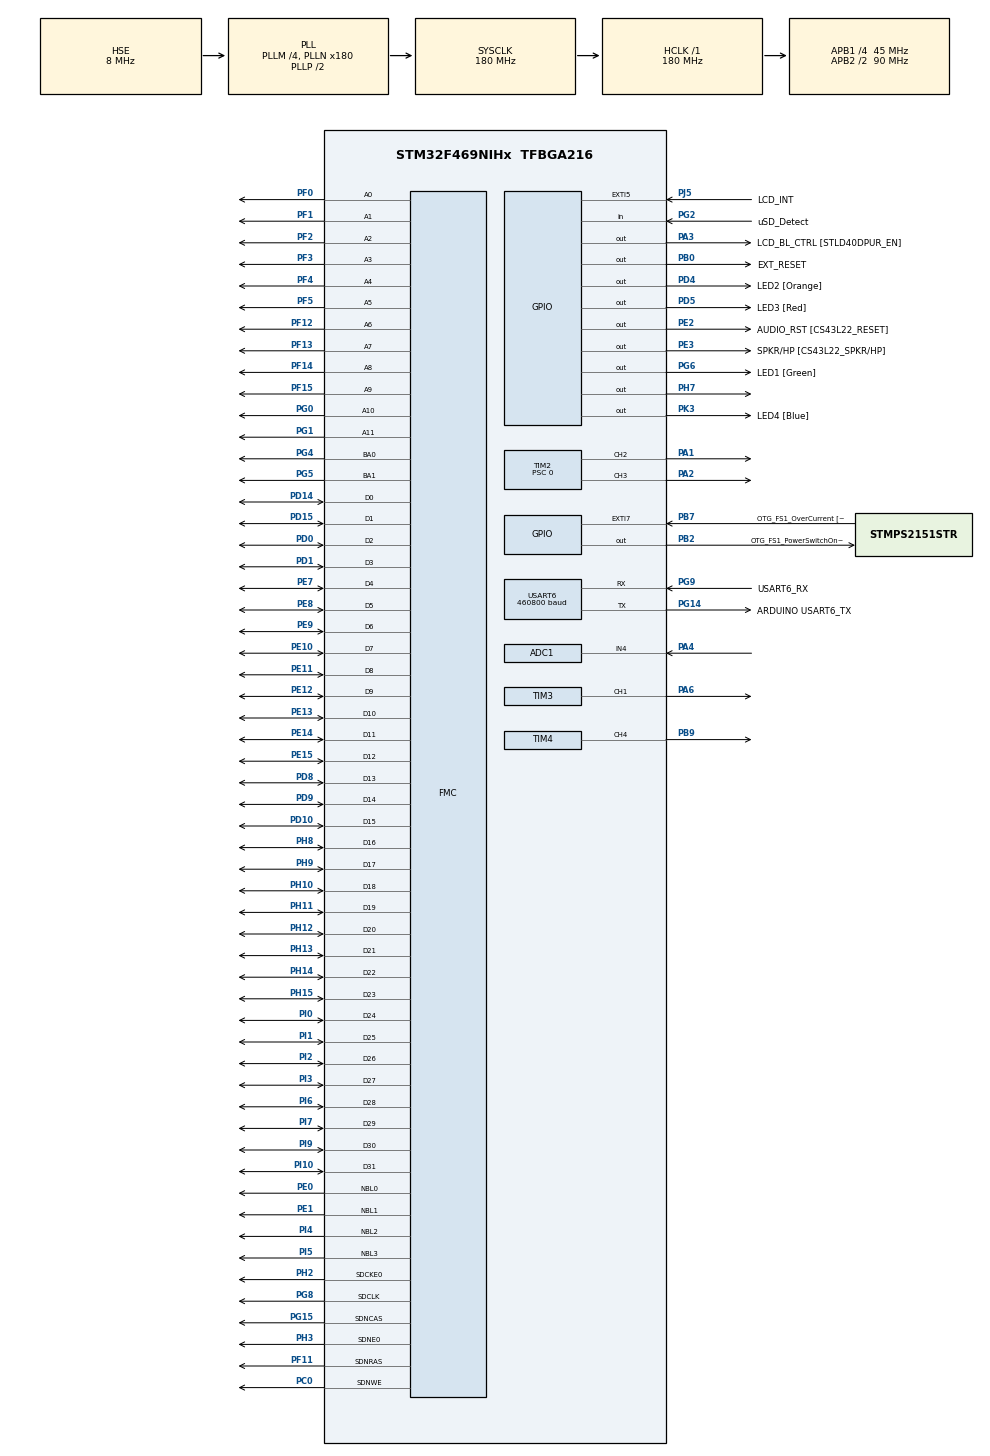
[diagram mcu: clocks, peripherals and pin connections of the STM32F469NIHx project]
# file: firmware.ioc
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ADC1.Channel-0\#ChannelRegularConversion=ADC_CHANNEL_4
ADC1.ExternalTrigConv=ADC_EXTERNALTRIGCONV_T4_CC4
ADC1.NbrOfConversion=1
ADC1.NbrOfConversionFlag=1
ADC1.Rank-0\#ChannelRegularConversion=1
ADC1.SamplingTime-0\#ChannelRegularConversion=ADC_SAMPLETIME_28CYCLES
ADC1.master=1
DSIHOST_CKN.GPIO_Label=DSI_CK_N
DSIHOST_CKN.Signal=DSIHOST_CKN
DSIHOST_CKP.GPIO_Label=DSI_CK_P
DSIHOST_CKP.Signal=DSIHOST_CKP
DSIHOST_D0N.GPIO_Label=DSI_D0_N
DSIHOST_D0N.Signal=DSIHOST_D0N
DSIHOST_D0P.GPIO_Label=DSI_D0_P
DSIHOST_D0P.Signal=DSIHOST_D0P
DSIHOST_D1N.GPIO_Label=DSI_D1_N
DSIHOST_D1N.Signal=DSIHOST_D1N
DSIHOST_D1P.GPIO_Label=DSI_D1_P
DSIHOST_D1P.Signal=DSIHOST_D1P
Dma.ADC1.2.Direction=DMA_PERIPH_TO_MEMORY
Dma.ADC1.2.FIFOMode=DMA_FIFOMODE_DISABLE
Dma.ADC1.2.Instance=DMA2_Stream0
Dma.ADC1.2.MemDataAlignment=DMA_MDATAALIGN_HALFWORD
Dma.ADC1.2.MemInc=DMA_MINC_ENABLE
Dma.ADC1.2.Mode=DMA_NORMAL
Dma.ADC1.2.PeriphDataAlignment=DMA_PDATAALIGN_HALFWORD
Dma.ADC1.2.PeriphInc=DMA_PINC_DISABLE
Dma.ADC1.2.Priority=DMA_PRIORITY_LOW
Dma.Request0=TIM2_UP/CH3
Dma.Request1=TIM2_CH2/CH4
Dma.Request2=ADC1
Dma.Request3=USART6_RX
Dma.Request4=USART6_TX
Dma.TIM2_CH2/CH4.1.Direction=DMA_MEMORY_TO_PERIPH
Dma.TIM2_CH2/CH4.1.FIFOMode=DMA_FIFOMODE_DISABLE
Dma.TIM2_CH2/CH4.1.Instance=DMA1_Stream6
Dma.TIM2_CH2/CH4.1.MemDataAlignment=DMA_MDATAALIGN_WORD
Dma.TIM2_CH2/CH4.1.MemInc=DMA_MINC_ENABLE
Dma.TIM2_CH2/CH4.1.Mode=DMA_CIRCULAR
Dma.TIM2_CH2/CH4.1.PeriphDataAlignment=DMA_PDATAALIGN_WORD
Dma.TIM2_CH2/CH4.1.PeriphInc=DMA_PINC_DISABLE
Dma.TIM2_CH2/CH4.1.Priority=DMA_PRIORITY_HIGH
Dma.TIM2_UP/CH3.0.Direction=DMA_MEMORY_TO_PERIPH
Dma.TIM2_UP/CH3.0.FIFOMode=DMA_FIFOMODE_DISABLE
Dma.TIM2_UP/CH3.0.Instance=DMA1_Stream1
Dma.TIM2_UP/CH3.0.MemDataAlignment=DMA_MDATAALIGN_WORD
Dma.TIM2_UP/CH3.0.MemInc=DMA_MINC_ENABLE
Dma.TIM2_UP/CH3.0.Mode=DMA_CIRCULAR
Dma.TIM2_UP/CH3.0.PeriphDataAlignment=DMA_PDATAALIGN_WORD
Dma.TIM2_UP/CH3.0.PeriphInc=DMA_PINC_DISABLE
Dma.TIM2_UP/CH3.0.Priority=DMA_PRIORITY_HIGH
Dma.USART6_RX.3.Direction=DMA_PERIPH_TO_MEMORY
Dma.USART6_RX.3.FIFOMode=DMA_FIFOMODE_DISABLE
Dma.USART6_RX.3.Instance=DMA2_Stream1
Dma.USART6_RX.3.MemDataAlignment=DMA_MDATAALIGN_BYTE
Dma.USART6_RX.3.MemInc=DMA_MINC_ENABLE
Dma.USART6_RX.3.Mode=DMA_CIRCULAR
Dma.USART6_RX.3.PeriphDataAlignment=DMA_PDATAALIGN_BYTE
Dma.USART6_RX.3.PeriphInc=DMA_PINC_DISABLE
Dma.USART6_RX.3.Priority=DMA_PRIORITY_MEDIUM
Dma.USART6_TX.4.Direction=DMA_MEMORY_TO_PERIPH
Dma.USART6_TX.4.FIFOMode=DMA_FIFOMODE_DISABLE
Dma.USART6_TX.4.Instance=DMA2_Stream6
Dma.USART6_TX.4.MemDataAlignment=DMA_MDATAALIGN_BYTE
Dma.USART6_TX.4.MemInc=DMA_MINC_ENABLE
Dma.USART6_TX.4.Mode=DMA_NORMAL
Dma.USART6_TX.4.PeriphDataAlignment=DMA_PDATAALIGN_BYTE
Dma.USART6_TX.4.PeriphInc=DMA_PINC_DISABLE
Dma.USART6_TX.4.Priority=DMA_PRIORITY_MEDIUM
FMC.CASLatency1=FMC_SDRAM_CAS_LATENCY_3
FMC.ExitSelfRefreshDelay1=6
FMC.LoadToActiveDelay1=2
FMC.RCDDelay1=2
FMC.RPDelay1=2
FMC.RPDelay2=2
FMC.ReadBurst1=FMC_SDRAM_RBURST_ENABLE
FMC.ReadBurst2=FMC_SDRAM_RBURST_ENABLE
FMC.RowCycleDelay1=6
FMC.RowCycleDelay2=6
FMC.SDClockPeriod1=FMC_SDRAM_CLOCK_PERIOD_2
FMC.SDClockPeriod2=FMC_SDRAM_CLOCK_PERIOD_2
FMC.SelfRefreshTime1=4
FMC.WriteRecoveryTime1=2
Mcu.Family=STM32F4
Mcu.Name=STM32F469NIHx
Mcu.Package=TFBGA216
NVIC.DMA1_Stream1_IRQn=true\:0\:0\:false\:false\:true\:false\:true\:true
NVIC.DMA1_Stream6_IRQn=true\:0\:0\:false\:false\:true\:false\:true\:true
NVIC.DMA2_Stream0_IRQn=true\:0\:0\:false\:false\:true\:false\:true\:true
NVIC.DMA2_Stream1_IRQn=true\:0\:0\:false\:false\:true\:false\:true\:true
NVIC.DMA2_Stream6_IRQn=true\:0\:0\:false\:false\:true\:false\:true\:true
NVIC.PriorityGroup=NVIC_PRIORITYGROUP_4
NVIC.TIM2_IRQn=true\:0\:0\:false\:false\:true\:true\:true\:true
NVIC.TIM3_IRQn=true\:0\:0\:false\:false\:true\:true\:true\:true
NVIC.TIM6_DAC_IRQn=true\:15\:0\:false\:false\:true\:false\:true\:true
NVIC.TimeBase=TIM6_DAC_IRQn
NVIC.TimeBaseIP=TIM6
NVIC.USART6_IRQn=true\:0\:0\:false\:false\:true\:true\:true\:true
PA0/WKUP.GPIO_Label=WAKEUP [B2]
PA0/WKUP.Mode=SYS_WakeUp0
PA0/WKUP.Signal=SYS_WKUP
PA1.Signal=S_TIM2_CH2
PA10.GPIO_Label=USB_FS1_ID
PA10.GPIO_Mode=GPIO_MODE_AF_PP
PA10.GPIO_PuPd=GPIO_NOPULL
PA10.GPIO_Speed=GPIO_SPEED_FREQ_VERY_HIGH
PA10.Signal=USB_OTG_FS_ID
PA11.GPIO_Label=USB_FS1_N
PA11.GPIO_Mode=GPIO_MODE_AF_PP
PA11.GPIO_PuPd=GPIO_NOPULL
PA11.GPIO_Speed=GPIO_SPEED_FREQ_VERY_HIGH
PA11.Signal=USB_OTG_FS_DM
PA12.GPIO_Label=USB_FS1_P
PA12.GPIO_Mode=GPIO_MODE_AF_PP
PA12.GPIO_PuPd=GPIO_NOPULL
PA12.GPIO_Speed=GPIO_SPEED_FREQ_VERY_HIGH
PA12.Signal=USB_OTG_FS_DP
PA13.GPIO_Label=SWDIO
PA13.Mode=Serial_Wire
PA13.Signal=SYS_JTMS-SWDIO
PA14.GPIO_Label=SWCLK
PA14.Mode=Serial_Wire
PA14.Signal=SYS_JTCK-SWCLK
PA2.GPIO_Speed=GPIO_SPEED_FREQ_HIGH
PA2.Signal=S_TIM2_CH3
PA3.GPIO_Label=LCD_BL_CTRL [STLD40DPUR_EN]
PA3.GPIO_ModeDefaultOutputPP=GPIO_MODE_OUTPUT_PP
PA3.GPIO_PuPd=GPIO_NOPULL
PA3.GPIO_Speed=GPIO_SPEED_FREQ_LOW
PA3.Signal=GPIO_Output
PA4.Signal=ADCx_IN4
PA6.Signal=S_TIM3_CH1
PA7.Signal=S_TIM3_CH2
PB0.GPIO_Label=EXT_RESET
PB0.GPIO_ModeDefaultOutputPP=GPIO_MODE_OUTPUT_PP
PB0.GPIO_PuPd=GPIO_NOPULL
PB0.GPIO_Speed=GPIO_SPEED_FREQ_LOW
PB0.Signal=GPIO_Output
PB1.Signal=S_TIM3_CH4
PB10.GPIO_Label=STLK_RX [STLINK V2-1_U2_RX]
PB10.GPIO_Mode=GPIO_MODE_AF_PP
PB10.GPIO_PuPd=GPIO_PULLUP
PB10.GPIO_Speed=GPIO_SPEED_FREQ_VERY_HIGH
PB10.Signal=USART3_TX
PB11.GPIO_Label=STLK_TX [STLINK V2-1_U2_TX]
PB11.GPIO_Mode=GPIO_MODE_AF_PP
PB11.GPIO_PuPd=GPIO_PULLUP
PB11.GPIO_Speed=GPIO_SPEED_FREQ_VERY_HIGH
PB11.Signal=USART3_RX
PB14.Signal=TIM1_CH2N
PB2/BOOT1.GPIO_Label=OTG_FS1_PowerSwitchOn [STMPS2151STR_En]
PB2/BOOT1.GPIO_ModeDefaultOutputPP=GPIO_MODE_OUTPUT_PP
PB2/BOOT1.GPIO_PuPd=GPIO_NOPULL
PB2/BOOT1.GPIO_Speed=GPIO_SPEED_FREQ_LOW
PB2/BOOT1.Signal=GPIO_Output
PB6.GPIO_Label=QSPI_BK1_NCS [N25Q128A13EF840F_S]
PB6.GPIO_Mode=GPIO_MODE_AF_PP
PB6.GPIO_PuPd=GPIO_NOPULL
PB6.GPIO_Speed=GPIO_SPEED_FREQ_VERY_HIGH
PB6.Signal=QUADSPI_BK1_NCS
PB7.GPIO_Label=OTG_FS1_OverCurrent [STMPS2151STR_FAULT]
PB7.GPIO_ModeDefaultEXTI=GPIO_MODE_IT_RISING
PB7.GPIO_PuPd=GPIO_NOPULL
PB7.Signal=GPXTI7
PB8.Signal=S_TIM4_CH3
PB9.Signal=S_TIM4_CH4
PC0.GPIO_Mode=GPIO_MODE_AF_PP
PC0.GPIO_PuPd=GPIO_NOPULL
PC0.GPIO_Speed_High_Default=GPIO_SPEED_FREQ_VERY_HIGH
PC0.Signal=FMC_SDNWE
PC10.GPIO_Label=uSD_D2
PC10.GPIO_Mode=GPIO_MODE_AF_PP
PC10.GPIO_PuPd=GPIO_NOPULL
PC10.GPIO_Speed_High_Default=GPIO_SPEED_FREQ_VERY_HIGH
PC10.Signal=SDIO_D2
PC11.GPIO_Label=uSD_D3
PC11.GPIO_Mode=GPIO_MODE_AF_PP
PC11.GPIO_PuPd=GPIO_NOPULL
PC11.GPIO_Speed_High_Default=GPIO_SPEED_FREQ_VERY_HIGH
PC11.Signal=SDIO_D3
PC12.GPIO_Label=uSD_CLK
PC12.GPIO_Mode=GPIO_MODE_AF_PP
PC12.GPIO_PuPd=GPIO_NOPULL
PC12.GPIO_Speed_High_Default=GPIO_SPEED_FREQ_VERY_HIGH
PC12.Signal=SDIO_CK
PC14/OSC32_IN.Mode=LSE-External-Oscillator
PC14/OSC32_IN.Signal=RCC_OSC32_IN
PC15/OSC32_OUT.Mode=LSE-External-Oscillator
PC15/OSC32_OUT.Signal=RCC_OSC32_OUT
PC8.GPIO_Label=uSD_D0
PC8.GPIO_Mode=GPIO_MODE_AF_PP
PC8.GPIO_PuPd=GPIO_NOPULL
PC8.GPIO_Speed_High_Default=GPIO_SPEED_FREQ_VERY_HIGH
PC8.Signal=SDIO_D0
PC9.GPIO_Label=uSD_D1
PC9.GPIO_Mode=GPIO_MODE_AF_PP
PC9.GPIO_PuPd=GPIO_NOPULL
PC9.GPIO_Speed_High_Default=GPIO_SPEED_FREQ_VERY_HIGH
PC9.Signal=SDIO_D1
PD0.GPIO_Mode=GPIO_MODE_AF_PP
PD0.GPIO_PuPd=GPIO_NOPULL
PD0.GPIO_Speed_High_Default=GPIO_SPEED_FREQ_VERY_HIGH
PD0.Signal=FMC_D2_DA2
PD1.GPIO_Mode=GPIO_MODE_AF_PP
PD1.GPIO_PuPd=GPIO_NOPULL
PD1.GPIO_Speed_High_Default=GPIO_SPEED_FREQ_VERY_HIGH
PD1.Signal=FMC_D3_DA3
PD10.GPIO_Mode=GPIO_MODE_AF_PP
PD10.GPIO_PuPd=GPIO_NOPULL
PD10.GPIO_Speed_High_Default=GPIO_SPEED_FREQ_VERY_HIGH
PD10.Signal=FMC_D15_DA15
PD13.GPIO_Label=MIC_CK [MP34DT01TR_CLK]
PD13.GPIO_ModeDefaultPP=GPIO_MODE_AF_PP
PD13.GPIO_PuPd=GPIO_NOPULL
PD13.GPIO_Speed=GPIO_SPEED_FREQ_LOW
PD13.Signal=S_TIM4_CH2
PD14.GPIO_Mode=GPIO_MODE_AF_PP
PD14.GPIO_PuPd=GPIO_NOPULL
PD14.GPIO_Speed_High_Default=GPIO_SPEED_FREQ_VERY_HIGH
PD14.Signal=FMC_D0_DA0
PD15.Signal=FMC_D1_DA1
PD2.GPIO_Label=uSD_CMD
PD2.GPIO_Mode=GPIO_MODE_AF_PP
PD2.GPIO_PuPd=GPIO_NOPULL
PD2.GPIO_Speed_High_Default=GPIO_SPEED_FREQ_VERY_HIGH
PD2.Signal=SDIO_CMD
PD4.GPIO_Label=LED2 [Orange]
PD4.GPIO_ModeDefaultOutputPP=GPIO_MODE_OUTPUT_OD
PD4.GPIO_PuPd=GPIO_NOPULL
PD4.GPIO_Speed=GPIO_SPEED_FREQ_LOW
PD4.Signal=GPIO_Output
PD5.GPIO_Label=LED3 [Red]
PD5.GPIO_ModeDefaultOutputPP=GPIO_MODE_OUTPUT_OD
PD5.GPIO_PuPd=GPIO_NOPULL
PD5.GPIO_Speed=GPIO_SPEED_FREQ_LOW
PD5.Signal=GPIO_Output
PD6.GPIO_Label=MIC_DATA [MP34DT01TR_DOUT]
PD6.GPIO_Mode=GPIO_MODE_AF_PP
PD6.GPIO_PuPd=GPIO_NOPULL
PD6.GPIO_Speed=GPIO_SPEED_FREQ_LOW
PD6.Signal=SAI1_SD_A
PD8.GPIO_Mode=GPIO_MODE_AF_PP
PD8.GPIO_PuPd=GPIO_NOPULL
PD8.GPIO_Speed_High_Default=GPIO_SPEED_FREQ_VERY_HIGH
PD8.Signal=FMC_D13_DA13
PD9.GPIO_Mode=GPIO_MODE_AF_PP
PD9.GPIO_PuPd=GPIO_NOPULL
PD9.GPIO_Speed_High_Default=GPIO_SPEED_FREQ_VERY_HIGH
PD9.Signal=FMC_D14_DA14
PE0.GPIO_Mode=GPIO_MODE_AF_PP
PE0.GPIO_PuPd=GPIO_NOPULL
PE0.GPIO_Speed_High_Default=GPIO_SPEED_FREQ_VERY_HIGH
PE0.Signal=FMC_NBL0
PE1.GPIO_Mode=GPIO_MODE_AF_PP
PE1.GPIO_PuPd=GPIO_NOPULL
PE1.GPIO_Speed_High_Default=GPIO_SPEED_FREQ_VERY_HIGH
PE1.Signal=FMC_NBL1
PE10.GPIO_Mode=GPIO_MODE_AF_PP
PE10.GPIO_PuPd=GPIO_NOPULL
PE10.GPIO_Speed_High_Default=GPIO_SPEED_FREQ_VERY_HIGH
PE10.Signal=FMC_D7_DA7
PE11.GPIO_Mode=GPIO_MODE_AF_PP
PE11.GPIO_PuPd=GPIO_NOPULL
PE11.GPIO_Speed_High_Default=GPIO_SPEED_FREQ_VERY_HIGH
PE11.Signal=FMC_D8_DA8
PE12.GPIO_Mode=GPIO_MODE_AF_PP
PE12.GPIO_PuPd=GPIO_NOPULL
PE12.GPIO_Speed_High_Default=GPIO_SPEED_FREQ_VERY_HIGH
PE12.Signal=FMC_D9_DA9
PE13.GPIO_Mode=GPIO_MODE_AF_PP
PE13.GPIO_PuPd=GPIO_NOPULL
PE13.GPIO_Speed_High_Default=GPIO_SPEED_FREQ_VERY_HIGH
PE13.Signal=FMC_D10_DA10
PE14.GPIO_Mode=GPIO_MODE_AF_PP
PE14.GPIO_PuPd=GPIO_NOPULL
PE14.GPIO_Speed_High_Default=GPIO_SPEED_FREQ_VERY_HIGH
PE14.Signal=FMC_D11_DA11
PE15.GPIO_Mode=GPIO_MODE_AF_PP
PE15.GPIO_PuPd=GPIO_NOPULL
PE15.GPIO_Speed_High_Default=GPIO_SPEED_FREQ_VERY_HIGH
PE15.Signal=FMC_D12_DA12
PE2.GPIO_Label=AUDIO_RST [CS43L22_RESET]
PE2.GPIO_ModeDefaultOutputPP=GPIO_MODE_OUTPUT_PP
PE2.GPIO_PuPd=GPIO_NOPULL
PE2.GPIO_Speed=GPIO_SPEED_FREQ_LOW
PE2.Signal=GPIO_Output
PE3.GPIO_Label=SPKR/HP [CS43L22_SPKR/HP]
PE3.GPIO_ModeDefaultOutputPP=GPIO_MODE_OUTPUT_PP
PE3.GPIO_PuPd=GPIO_NOPULL
PE3.GPIO_Speed=GPIO_SPEED_FREQ_LOW
PE3.Signal=GPIO_Output
PE4.GPIO_Label=SAI1_FSA [CS43L22_LRCK]
PE4.GPIO_Mode=GPIO_MODE_AF_PP
PE4.GPIO_PuPd=GPIO_NOPULL
PE4.GPIO_Speed=GPIO_SPEED_FREQ_LOW
PE4.Signal=SAI1_FS_A
PE5.GPIO_Label=SAI1_SCKA [CS43L22_CLK]
PE5.GPIO_Mode=GPIO_MODE_AF_PP
PE5.GPIO_PuPd=GPIO_NOPULL
PE5.GPIO_Speed=GPIO_SPEED_FREQ_LOW
PE5.Signal=SAI1_SCK_A
PE7.GPIO_Mode=GPIO_MODE_AF_PP
PE7.GPIO_PuPd=GPIO_NOPULL
PE7.GPIO_Speed_High_Default=GPIO_SPEED_FREQ_VERY_HIGH
PE7.Signal=FMC_D4_DA4
PE8.GPIO_Mode=GPIO_MODE_AF_PP
PE8.GPIO_PuPd=GPIO_NOPULL
PE8.GPIO_Speed_High_Default=GPIO_SPEED_FREQ_VERY_HIGH
PE8.Signal=FMC_D5_DA5
PE9.GPIO_Mode=GPIO_MODE_AF_PP
PE9.GPIO_PuPd=GPIO_NOPULL
PE9.GPIO_Speed_High_Default=GPIO_SPEED_FREQ_VERY_HIGH
PE9.Signal=FMC_D6_DA6
PF0.GPIO_Mode=GPIO_MODE_AF_PP
PF0.GPIO_PuPd=GPIO_NOPULL
PF0.GPIO_Speed_High_Default=GPIO_SPEED_FREQ_VERY_HIGH
PF0.Signal=FMC_A0
PF1.GPIO_Mode=GPIO_MODE_AF_PP
PF1.GPIO_PuPd=GPIO_NOPULL
PF1.GPIO_Speed_High_Default=GPIO_SPEED_FREQ_VERY_HIGH
PF1.Signal=FMC_A1
PF10.GPIO_Label=QSPI_CLK [N25Q128A13EF840F_C]
PF10.GPIO_Mode=GPIO_MODE_AF_PP
PF10.GPIO_PuPd=GPIO_NOPULL
PF10.GPIO_Speed=GPIO_SPEED_FREQ_VERY_HIGH
PF10.Signal=QUADSPI_CLK
PF11.GPIO_Mode=GPIO_MODE_AF_PP
PF11.GPIO_PuPd=GPIO_NOPULL
PF11.GPIO_Speed_High_Default=GPIO_SPEED_FREQ_VERY_HIGH
PF11.Signal=FMC_SDNRAS
PF12.GPIO_Mode=GPIO_MODE_AF_PP
PF12.GPIO_PuPd=GPIO_NOPULL
PF12.GPIO_Speed_High_Default=GPIO_SPEED_FREQ_VERY_HIGH
PF12.Signal=FMC_A6
PF13.GPIO_Mode=GPIO_MODE_AF_PP
PF13.GPIO_PuPd=GPIO_NOPULL
PF13.GPIO_Speed_High_Default=GPIO_SPEED_FREQ_VERY_HIGH
PF13.Signal=FMC_A7
PF14.GPIO_Mode=GPIO_MODE_AF_PP
PF14.GPIO_PuPd=GPIO_NOPULL
PF14.GPIO_Speed_High_Default=GPIO_SPEED_FREQ_VERY_HIGH
PF14.Signal=FMC_A8
PF15.GPIO_Mode=GPIO_MODE_AF_PP
PF15.GPIO_PuPd=GPIO_NOPULL
PF15.GPIO_Speed_High_Default=GPIO_SPEED_FREQ_VERY_HIGH
PF15.Signal=FMC_A9
PF2.GPIO_Mode=GPIO_MODE_AF_PP
PF2.GPIO_PuPd=GPIO_NOPULL
PF2.GPIO_Speed_High_Default=GPIO_SPEED_FREQ_VERY_HIGH
PF2.Signal=FMC_A2
PF3.GPIO_Mode=GPIO_MODE_AF_PP
PF3.GPIO_PuPd=GPIO_NOPULL
PF3.GPIO_Speed_High_Default=GPIO_SPEED_FREQ_VERY_HIGH
PF3.Signal=FMC_A3
PF4.GPIO_Mode=GPIO_MODE_AF_PP
PF4.GPIO_PuPd=GPIO_NOPULL
PF4.GPIO_Speed_High_Default=GPIO_SPEED_FREQ_VERY_HIGH
PF4.Signal=FMC_A4
PF5.GPIO_Mode=GPIO_MODE_AF_PP
PF5.GPIO_PuPd=GPIO_NOPULL
PF5.GPIO_Speed_High_Default=GPIO_SPEED_FREQ_VERY_HIGH
PF5.Signal=FMC_A5
PF6.GPIO_Label=QSPI_BK1_IO3 [N25Q128A13EF840F_DQ3]
PF6.GPIO_Mode=GPIO_MODE_AF_PP
PF6.GPIO_PuPd=GPIO_NOPULL
PF6.GPIO_Speed=GPIO_SPEED_FREQ_VERY_HIGH
PF6.Signal=QUADSPI_BK1_IO3
PF7.GPIO_Label=QSPI_BK1_IO2 [N25Q128A13EF840F_DQ2]
PF7.GPIO_Mode=GPIO_MODE_AF_PP
PF7.GPIO_PuPd=GPIO_NOPULL
PF7.GPIO_Speed=GPIO_SPEED_FREQ_VERY_HIGH
PF7.Signal=QUADSPI_BK1_IO2
PF8.GPIO_Label=QSPI_BK1_IO0 [N25Q128A13EF840F_DQ0]
PF8.GPIO_Mode=GPIO_MODE_AF_PP
PF8.GPIO_PuPd=GPIO_NOPULL
PF8.GPIO_Speed=GPIO_SPEED_FREQ_VERY_HIGH
PF8.Signal=QUADSPI_BK1_IO0
PF9.GPIO_Label=QSPI_BK1_IO1 [N25Q128A13EF840F_DQ1]
PF9.GPIO_Mode=GPIO_MODE_AF_PP
PF9.GPIO_PuPd=GPIO_NOPULL
PF9.GPIO_Speed=GPIO_SPEED_FREQ_VERY_HIGH
PF9.Signal=QUADSPI_BK1_IO1
PG0.GPIO_Mode=GPIO_MODE_AF_PP
PG0.GPIO_PuPd=GPIO_NOPULL
PG0.GPIO_Speed_High_Default=GPIO_SPEED_FREQ_VERY_HIGH
PG0.Signal=FMC_A10
PG1.GPIO_Mode=GPIO_MODE_AF_PP
PG1.GPIO_PuPd=GPIO_NOPULL
PG1.GPIO_Speed_High_Default=GPIO_SPEED_FREQ_VERY_HIGH
PG1.Signal=FMC_A11
PG14.GPIO_Label=ARDUINO USART6_TX
PG14.GPIO_Mode=GPIO_MODE_AF_PP
PG14.GPIO_PuPd=GPIO_NOPULL
PG14.GPIO_Speed=GPIO_SPEED_FREQ_VERY_HIGH
PG14.Mode=Asynchronous
PG14.Signal=USART6_TX
PG15.GPIO_Mode=GPIO_MODE_AF_PP
PG15.GPIO_PuPd=GPIO_NOPULL
PG15.GPIO_Speed_High_Default=GPIO_SPEED_FREQ_VERY_HIGH
PG15.Signal=FMC_SDNCAS
PG2.GPIO_Label=uSD_Detect
PG2.GPIO_Mode=GPIO_MODE_INPUT
PG2.GPIO_PuPd=GPIO_NOPULL
PG2.Signal=GPIO_Input
PG4.Signal=FMC_A14_BA0
PG5.Signal=FMC_A15_BA1
PG6.GPIO_Label=LED1 [Green]
PG6.GPIO_ModeDefaultOutputPP=GPIO_MODE_OUTPUT_OD
PG6.GPIO_PuPd=GPIO_NOPULL
PG6.GPIO_Speed=GPIO_SPEED_FREQ_LOW
PG6.Signal=GPIO_Output
PG7.GPIO_Label=SAI1_MCLKA [CS43L22_MCLK]
PG7.GPIO_Mode=GPIO_MODE_AF_PP
PG7.GPIO_PuPd=GPIO_NOPULL
PG7.GPIO_Speed=GPIO_SPEED_FREQ_LOW
PG7.Signal=SAI1_MCLK_A
PG8.GPIO_Mode=GPIO_MODE_AF_PP
PG8.GPIO_PuPd=GPIO_NOPULL
PG8.GPIO_Speed_High_Default=GPIO_SPEED_FREQ_VERY_HIGH
PG8.Signal=FMC_SDCLK
PG9.GPIO_Label=USART6_RX
PG9.GPIO_Mode=GPIO_MODE_AF_PP
PG9.GPIO_PuPd=GPIO_NOPULL
PG9.GPIO_Speed=GPIO_SPEED_FREQ_VERY_HIGH
PG9.Mode=Asynchronous
PG9.Signal=USART6_RX
PH0/OSC_IN.Mode=HSE-External-Oscillator
PH0/OSC_IN.Signal=RCC_OSC_IN
PH1/OSC_OUT.Mode=HSE-External-Oscillator
PH1/OSC_OUT.Signal=RCC_OSC_OUT
PH10.GPIO_Mode=GPIO_MODE_AF_PP
PH10.GPIO_PuPd=GPIO_NOPULL
PH10.GPIO_Speed_High_Default=GPIO_SPEED_FREQ_VERY_HIGH
PH10.Signal=FMC_D18
PH11.GPIO_Mode=GPIO_MODE_AF_PP
PH11.GPIO_PuPd=GPIO_NOPULL
PH11.GPIO_Speed_High_Default=GPIO_SPEED_FREQ_VERY_HIGH
PH11.Signal=FMC_D19
PH12.GPIO_Mode=GPIO_MODE_AF_PP
PH12.GPIO_PuPd=GPIO_NOPULL
PH12.GPIO_Speed_High_Default=GPIO_SPEED_FREQ_VERY_HIGH
PH12.Signal=FMC_D20
PH13.GPIO_Mode=GPIO_MODE_AF_PP
PH13.GPIO_PuPd=GPIO_NOPULL
PH13.GPIO_Speed_High_Default=GPIO_SPEED_FREQ_VERY_HIGH
PH13.Signal=FMC_D21
PH14.GPIO_Mode=GPIO_MODE_AF_PP
PH14.GPIO_PuPd=GPIO_NOPULL
PH14.GPIO_Speed_High_Default=GPIO_SPEED_FREQ_VERY_HIGH
PH14.Signal=FMC_D22
PH15.GPIO_Mode=GPIO_MODE_AF_PP
PH15.GPIO_PuPd=GPIO_NOPULL
PH15.GPIO_Speed_High_Default=GPIO_SPEED_FREQ_VERY_HIGH
PH15.Signal=FMC_D23
PH2.GPIO_Mode=GPIO_MODE_AF_PP
PH2.GPIO_PuPd=GPIO_NOPULL
PH2.GPIO_Speed_High_Default=GPIO_SPEED_FREQ_VERY_HIGH
PH2.Mode=SdramChipSelect1_1
PH2.Signal=FMC_SDCKE0
PH3.GPIO_Mode=GPIO_MODE_AF_PP
PH3.GPIO_PuPd=GPIO_NOPULL
PH3.GPIO_Speed_High_Default=GPIO_SPEED_FREQ_VERY_HIGH
PH3.Mode=SdramChipSelect1_1
PH3.Signal=FMC_SDNE0
PH4.GPIO_Label=I2C2_SCL [CS43L22_SCL]
PH4.GPIO_Mode=GPIO_MODE_AF_OD
PH4.GPIO_Pu=GPIO_PULLUP
PH4.GPIO_Speed=GPIO_SPEED_FREQ_VERY_HIGH
PH4.Signal=I2C2_SCL
PH5.GPIO_Label=I2C2_SDA [CS43L22_SDA]
PH5.GPIO_Mode=GPIO_MODE_AF_OD
PH5.GPIO_Pu=GPIO_PULLUP
PH5.GPIO_Speed=GPIO_SPEED_FREQ_VERY_HIGH
PH5.Signal=I2C2_SDA
PH7.Signal=GPIO_Output
PH8.GPIO_Mode=GPIO_MODE_AF_PP
PH8.GPIO_PuPd=GPIO_NOPULL
PH8.GPIO_Speed_High_Default=GPIO_SPEED_FREQ_VERY_HIGH
PH8.Signal=FMC_D16
PH9.GPIO_Mode=GPIO_MODE_AF_PP
PH9.GPIO_PuPd=GPIO_NOPULL
PH9.GPIO_Speed_High_Default=GPIO_SPEED_FREQ_VERY_HIGH
PH9.Signal=FMC_D17
PI0.GPIO_Mode=GPIO_MODE_AF_PP
PI0.GPIO_PuPd=GPIO_NOPULL
PI0.GPIO_Speed_High_Default=GPIO_SPEED_FREQ_VERY_HIGH
PI0.Signal=FMC_D24
PI1.GPIO_Mode=GPIO_MODE_AF_PP
PI1.GPIO_PuPd=GPIO_NOPULL
PI1.GPIO_Speed_High_Default=GPIO_SPEED_FREQ_VERY_HIGH
PI1.Signal=FMC_D25
PI10.GPIO_Mode=GPIO_MODE_AF_PP
PI10.GPIO_PuPd=GPIO_NOPULL
PI10.GPIO_Speed_High_Default=GPIO_SPEED_FREQ_VERY_HIGH
PI10.Signal=FMC_D31
PI2.GPIO_Mode=GPIO_MODE_AF_PP
PI2.GPIO_PuPd=GPIO_NOPULL
PI2.GPIO_Speed_High_Default=GPIO_SPEED_FREQ_VERY_HIGH
PI2.Signal=FMC_D26
PI3.GPIO_Mode=GPIO_MODE_AF_PP
PI3.GPIO_PuPd=GPIO_NOPULL
PI3.GPIO_Speed_High_Default=GPIO_SPEED_FREQ_VERY_HIGH
PI3.Signal=FMC_D27
PI4.GPIO_Mode=GPIO_MODE_AF_PP
PI4.GPIO_PuPd=GPIO_NOPULL
PI4.GPIO_Speed_High_Default=GPIO_SPEED_FREQ_VERY_HIGH
PI4.Signal=FMC_NBL2
PI5.GPIO_Mode=GPIO_MODE_AF_PP
PI5.GPIO_PuPd=GPIO_NOPULL
PI5.GPIO_Speed_High_Default=GPIO_SPEED_FREQ_VERY_HIGH
PI5.Signal=FMC_NBL3
PI6.GPIO_Mode=GPIO_MODE_AF_PP
PI6.GPIO_PuPd=GPIO_NOPULL
PI6.GPIO_Speed_High_Default=GPIO_SPEED_FREQ_VERY_HIGH
PI6.Signal=FMC_D28
PI7.GPIO_Mode=GPIO_MODE_AF_PP
PI7.GPIO_PuPd=GPIO_NOPULL
PI7.GPIO_Speed_High_Default=GPIO_SPEED_FREQ_VERY_HIGH
PI7.Signal=FMC_D29
PI9.GPIO_Mode=GPIO_MODE_AF_PP
PI9.GPIO_PuPd=GPIO_NOPULL
PI9.GPIO_Speed_High_Default=GPIO_SPEED_FREQ_VERY_HIGH
PI9.Signal=FMC_D30
PJ2.GPIO_Label=DSI_TE
PJ2.GPIO_Mode=GPIO_MODE_AF_PP
PJ2.GPIO_PuPd=GPIO_NOPULL
PJ2.GPIO_Speed=GPIO_SPEED_FREQ_VERY_HIGH
PJ2.Signal=DSIHOST_TE
PJ5.GPIO_Label=LCD_INT
PJ5.GPIO_ModeDefaultEXTI=GPIO_MODE_IT_RISING
PJ5.GPIO_PuPd=GPIO_NOPULL
PJ5.Signal=GPXTI5
PK3.GPIO_Label=LED4 [Blue]
PK3.GPIO_ModeDefaultOutputPP=GPIO_MODE_OUTPUT_OD
PK3.GPIO_PuPd=GPIO_NOPULL
PK3.GPIO_Speed=GPIO_SPEED_FREQ_LOW
PK3.Signal=GPIO_Output
ProjectManager.HeapSize=0x200
ProjectManager.StackSize=0x400
ProjectManager.TargetToolchain=STM32CubeIDE
RCC.AHBFreq_Value=180000000
RCC.APB1CLKDivider=RCC_HCLK_DIV4
RCC.APB1Freq_Value=45000000
RCC.APB1TimFreq_Value=90000000
RCC.APB2CLKDivider=RCC_HCLK_DIV2
RCC.APB2Freq_Value=90000000
RCC.APB2TimFreq_Value=180000000
RCC.CortexFreq_Value=180000000
RCC.HCLKFreq_Value=180000000
RCC.HSE_VALUE=8000000
RCC.PLLDSIIDF=DSI_PLL_IN_DIV2
RCC.PLLDSINDIV=125
RCC.PLLM=4
RCC.PLLN=180
RCC.PLLQ=6
RCC.PLLR=6
RCC.PLLSAIN=144
RCC.PLLSAIP=RCC_PLLSAIP_DIV6
RCC.PLLSAIQ=2
RCC.PLLSAIRDiv=RCC_PLLSAIDIVR_4
RCC.PLLSourceVirtual=RCC_PLLSOURCE_HSE
RCC.SYSCLKFreq_VALUE=180000000
RCC.SYSCLKSource=RCC_SYSCLKSOURCE_PLLCLK
RCC.USBCLockSelection=RCC_CLK48CLKSOURCE_PLLSAIP
RCC.USBFreq_Value=48000000
RCC.VCOOutputFreq_Value=360000000
SH.ADCx_IN4.0=ADC1_IN4,IN4
SH.FMC_A0.0=FMC_A0,12b-sda1
SH.FMC_A1.0=FMC_A1,12b-sda1
SH.FMC_A10.0=FMC_A10,12b-sda1
SH.FMC_A11.0=FMC_A11,12b-sda1
SH.FMC_A14_BA0.0=FMC_BA0,FourSdramBanks1
SH.FMC_A15_BA1.0=FMC_BA1,FourSdramBanks1
SH.FMC_A2.0=FMC_A2,12b-sda1
SH.FMC_A3.0=FMC_A3,12b-sda1
SH.FMC_A4.0=FMC_A4,12b-sda1
SH.FMC_A5.0=FMC_A5,12b-sda1
SH.FMC_A6.0=FMC_A6,12b-sda1
SH.FMC_A7.0=FMC_A7,12b-sda1
SH.FMC_A8.0=FMC_A8,12b-sda1
SH.FMC_A9.0=FMC_A9,12b-sda1
SH.FMC_D0_DA0.0=FMC_D0,sd-32b-d1
SH.FMC_D10_DA10.0=FMC_D10,sd-32b-d1
SH.FMC_D11_DA11.0=FMC_D11,sd-32b-d1
SH.FMC_D12_DA12.0=FMC_D12,sd-32b-d1
SH.FMC_D13_DA13.0=FMC_D13,sd-32b-d1
SH.FMC_D14_DA14.0=FMC_D14,sd-32b-d1
SH.FMC_D15_DA15.0=FMC_D15,sd-32b-d1
SH.FMC_D16.0=FMC_D16,sd-32b-d1
SH.FMC_D17.0=FMC_D17,sd-32b-d1
SH.FMC_D18.0=FMC_D18,sd-32b-d1
SH.FMC_D19.0=FMC_D19,sd-32b-d1
SH.FMC_D1_DA1.0=FMC_D1,sd-32b-d1
SH.FMC_D20.0=FMC_D20,sd-32b-d1
SH.FMC_D21.0=FMC_D21,sd-32b-d1
SH.FMC_D22.0=FMC_D22,sd-32b-d1
SH.FMC_D23.0=FMC_D23,sd-32b-d1
SH.FMC_D24.0=FMC_D24,sd-32b-d1
SH.FMC_D25.0=FMC_D25,sd-32b-d1
SH.FMC_D26.0=FMC_D26,sd-32b-d1
SH.FMC_D27.0=FMC_D27,sd-32b-d1
SH.FMC_D28.0=FMC_D28,sd-32b-d1
SH.FMC_D29.0=FMC_D29,sd-32b-d1
SH.FMC_D2_DA2.0=FMC_D2,sd-32b-d1
SH.FMC_D30.0=FMC_D30,sd-32b-d1
SH.FMC_D31.0=FMC_D31,sd-32b-d1
SH.FMC_D3_DA3.0=FMC_D3,sd-32b-d1
SH.FMC_D4_DA4.0=FMC_D4,sd-32b-d1
SH.FMC_D5_DA5.0=FMC_D5,sd-32b-d1
SH.FMC_D6_DA6.0=FMC_D6,sd-32b-d1
SH.FMC_D7_DA7.0=FMC_D7,sd-32b-d1
SH.FMC_D8_DA8.0=FMC_D8,sd-32b-d1
SH.FMC_D9_DA9.0=FMC_D9,sd-32b-d1
SH.FMC_NBL0.0=FMC_NBL0,Sd4ByteEnable1
SH.FMC_NBL1.0=FMC_NBL1,Sd4ByteEnable1
SH.FMC_NBL2.0=FMC_NBL2,Sd4ByteEnable1
SH.FMC_NBL3.0=FMC_NBL3,Sd4ByteEnable1
SH.FMC_SDCLK.0=FMC_SDCLK,12b-sda1
SH.FMC_SDNCAS.0=FMC_SDNCAS,12b-sda1
SH.FMC_SDNRAS.0=FMC_SDNRAS,12b-sda1
SH.FMC_SDNWE.0=FMC_SDNWE,12b-sda1
SH.S_TIM2_CH2.0=TIM2_CH2,Output Compare2 CH2
SH.S_TIM2_CH3.0=TIM2_CH3,Output Compare3 CH3
SH.S_TIM3_CH1.0=TIM3_CH1,PWM Generation1 CH1
SH.S_TIM3_CH2.0=TIM3_CH2
SH.S_TIM3_CH4.0=TIM3_CH4
SH.S_TIM4_CH2.0=TIM4_CH2
SH.S_TIM4_CH3.0=TIM4_CH3
SH.S_TIM4_CH4.0=TIM4_CH4,PWM Generation4 CH4
TIM2.Channel-Output\ Compare2\ CH2=TIM_CHANNEL_2
TIM2.Channel-Output\ Compare3\ CH3=TIM_CHANNEL_3
TIM2.OC2Preload=DISABLE
TIM2.OC3Preload=DISABLE
TIM2.OCMode_2=TIM_OCMODE_TOGGLE
TIM2.OCMode_3=TIM_OCMODE_TOGGLE
TIM2.OCPolarity_2=TIM_OCPOLARITY_LOW
TIM2.OCPolarity_3=TIM_OCPOLARITY_HIGH
TIM2.Period=720200
TIM2.Prescaler=0
TIM2.Pulse-Output\ Compare2\ CH2=50
TIM2.Pulse-Output\ Compare3\ CH3=0
TIM2.TIM_MasterOutputTrigger=TIM_TRGO_RESET
TIM2.TIM_MasterSlaveMode=TIM_MASTERSLAVEMODE_DISABLE
TIM3.Channel-PWM\ Generation1\ CH1=TIM_CHANNEL_1
TIM3.Period=44
TIM3.Pulse-PWM\ Generation1\ CH1=22
TIM3.TIM_MasterOutputTrigger=TIM_TRGO_UPDATE
TIM3.TIM_MasterSlaveMode=TIM_MASTERSLAVEMODE_ENABLE
TIM4.Channel-PWM\ Generation4\ CH4=TIM_CHANNEL_4
TIM4.OCPolarity_4=TIM_OCPOLARITY_LOW
TIM4.Period=3
TIM4.Pulse-PWM\ Generation4\ CH4=3
USART6.BaudRate=460800
USART6.VirtualMode=VM_ASYNC
VP_SYS_VS_tim6.Mode=TIM6
VP_TIM2_VS_ClockSourceITR.Mode=TriggerSource_ITR2
VP_TIM2_VS_ControllerModeClock.Mode=Clock Mode
VP_TIM3_VS_ClockSourceINT.Mode=Internal
VP_TIM4_VS_ClockSourceITR.Mode=TriggerSource_ITR2
VP_TIM4_VS_ControllerModeClock.Mode=Clock Mode
board=STM32F469I-DISCO

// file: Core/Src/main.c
/* USER CODE BEGIN Header */
/**
  ******************************************************************************
  * @file           : main.c
  * @brief          : Main program body
  ******************************************************************************
  * @attention
  *
  *
  ******************************************************************************
  */
/* USER CODE END Header */
#include "main.h"

/* USER CODE BEGIN Includes */
#include <stdio.h>
#include <string.h>
#include <tcd_process_instructions.h>
#include <tcd_sdram_manage.h>
#include <tcd_send_data.h>
#include <tcd_signals.h>
#include "tcd_callbacks.h"
#include "tcd_variables.h"

/* USER CODE END Includes */

ADC_HandleTypeDef hadc1;
DMA_HandleTypeDef hdma_adc1;

TIM_HandleTypeDef htim2;
TIM_HandleTypeDef htim3;
TIM_HandleTypeDef htim4;
DMA_HandleTypeDef hdma_tim2_up_ch3;
DMA_HandleTypeDef hdma_tim2_ch2_ch4;

UART_HandleTypeDef huart6;
DMA_HandleTypeDef hdma_usart6_rx;
DMA_HandleTypeDef hdma_usart6_tx;

SDRAM_HandleTypeDef hsdram1;

/* USER CODE BEGIN PV */
extern volatile uint8_t is_flushing;
extern volatile uint8_t rx_cmd_buffer[SIZE_RX_BUFFER_CMD_8];
extern volatile uint8_t send_now;
extern volatile uint8_t continuous_mode;
extern volatile uint8_t process_instruction_flag;
extern volatile uint16_t cmd;
extern volatile uint16_t number_of_accumulations;
extern volatile uint8_t processing;

/* USER CODE END PV */

void SystemClock_Config(void);
static void MX_GPIO_Init(void);
static void MX_DMA_Init(void);
static void MX_USART6_UART_Init(void);
static void MX_TIM2_Init(void);
static void MX_TIM3_Init(void);
static void MX_ADC1_Init(void);
static void MX_FMC_Init(void);
static void MX_TIM4_Init(void);

int main(void)
{

  /* MCU Configuration--------------------------------------------------------*/

  /* Reset of all peripherals, Initializes the Flash interface and the Systick. */
  HAL_Init();

  /* Configure the system clock */
  SystemClock_Config();

  /* Initialize all configured peripherals */
  MX_GPIO_Init();
  MX_DMA_Init();
  MX_USART6_UART_Init();
  MX_TIM2_Init();
  MX_TIM3_Init();
  MX_ADC1_Init();
  MX_FMC_Init();
  MX_TIM4_Init();
  /* USER CODE BEGIN 2 */

  int i = 0;

  calculate_times(T_INT_DEFAULT);

  build_SH_table();

  setup_timer_icg_sh();
  start_timers(1);

  HAL_Delay(100);
  is_flushing = 0;

  HAL_UART_Receive_DMA(&huart6, (uint8_t*) rx_cmd_buffer, SIZE_RX_BUFFER_CMD_8);

  /* USER CODE END 2 */

  /* Infinite loop */
  /* USER CODE BEGIN WHILE */
  while (1) {
	  if(send_now == 1){
		  if(continuous_mode == 1){
			  send_data_continuous_dma();
		  } else if (continuous_mode == 0){
			  send_data_fixed_length_dma();
		  }
	  }

	  if(process_instruction_flag == 1){
		  if(cmd == RESET_DEVICE){
				start_timers(0);

				NVIC_SystemReset();
		  }

		  else{
			  start_timers(0);

			  switch(cmd){
				  case SET_INTEGRATION_TIME:{
					  uint16_t *p_words = (uint16_t*)rx_cmd_buffer;
					  uint32_t t_int_recibido = (p_words[3] << 16) | p_words[2];
					  calculate_times(t_int_recibido);
					  build_SH_table();
					  continuous_mode = -1;
					  break;
				  }

				  case SET_NUMBER_OF_ACCUMULATIONS:{
					  uint16_t *p_words = (uint16_t*)rx_cmd_buffer;
					  uint32_t n_accum_recibido = (p_words[3] << 16) | p_words[2];
					  number_of_accumulations = n_accum_recibido;
					  continuous_mode = -1;
					  break;
				  }

				  case FIXED_LENGTH_MODE_ENABLE:{
					  continuous_mode = 0;
					  break;
				  }

				  case CONTINUOUS_MODE_ENABLE:
					  continuous_mode = 1;
					  break;

				  default:
						break;
			  }

			  setup_timer_icg_sh();

			  reset_parameters();

			  start_timers(1);

			  HAL_Delay(50);
			  is_flushing = 0;
		  }

		  process_instruction_flag = 0;
	  }	// END IF INSTRUCTION FLAG

	  if(i > 10){
		  HAL_GPIO_TogglePin(LED1_GPIO_Port, LED1_Pin);
	  	  i = 0;
	  }

	  i++;
	  HAL_Delay(100);
    /* USER CODE END WHILE */

    /* USER CODE BEGIN 3 */

  }	// END WHILE

  /* USER CODE END 3 */
}

void SystemClock_Config(void)
{
  RCC_OscInitTypeDef RCC_OscInitStruct = {0};
  RCC_ClkInitTypeDef RCC_ClkInitStruct = {0};

  /** Configure the main internal regulator output voltage
  */
  __HAL_RCC_PWR_CLK_ENABLE();
  __HAL_PWR_VOLTAGESCALING_CONFIG(PWR_REGULATOR_VOLTAGE_SCALE1);

  /** Initializes the RCC Oscillators according to the specified parameters
  * in the RCC_OscInitTypeDef structure.
  */
  RCC_OscInitStruct.OscillatorType = RCC_OSCILLATORTYPE_HSE;
  RCC_OscInitStruct.HSEState = RCC_HSE_ON;
  RCC_OscInitStruct.PLL.PLLState = RCC_PLL_ON;
  RCC_OscInitStruct.PLL.PLLSource = RCC_PLLSOURCE_HSE;
  RCC_OscInitStruct.PLL.PLLM = 4;
  RCC_OscInitStruct.PLL.PLLN = 180;
  RCC_OscInitStruct.PLL.PLLP = RCC_PLLP_DIV2;
  RCC_OscInitStruct.PLL.PLLQ = 6;
  RCC_OscInitStruct.PLL.PLLR = 6;
  if (HAL_RCC_OscConfig(&RCC_OscInitStruct) != HAL_OK)
  {
    Error_Handler();
  }

  /** Activate the Over-Drive mode
  */
  if (HAL_PWREx_EnableOverDrive() != HAL_OK)
  {
    Error_Handler();
  }

  /** Initializes the CPU, AHB and APB buses clocks
  */
  RCC_ClkInitStruct.ClockType = RCC_CLOCKTYPE_HCLK|RCC_CLOCKTYPE_SYSCLK
                              |RCC_CLOCKTYPE_PCLK1|RCC_CLOCKTYPE_PCLK2;
  RCC_ClkInitStruct.SYSCLKSource = RCC_SYSCLKSOURCE_PLLCLK;
  RCC_ClkInitStruct.AHBCLKDivider = RCC_SYSCLK_DIV1;
  RCC_ClkInitStruct.APB1CLKDivider = RCC_HCLK_DIV4;
  RCC_ClkInitStruct.APB2CLKDivider = RCC_HCLK_DIV2;

  if (HAL_RCC_ClockConfig(&RCC_ClkInitStruct, FLASH_LATENCY_5) != HAL_OK)
  {
    Error_Handler();
  }
}

static void MX_ADC1_Init(void)
{

  ADC_ChannelConfTypeDef sConfig = {0};

  /** Configure the global features of the ADC (Clock, Resolution, Data Alignment and number of conversion)
  */
  hadc1.Instance = ADC1;
  hadc1.Init.ClockPrescaler = ADC_CLOCK_SYNC_PCLK_DIV4;
  hadc1.Init.Resolution = ADC_RESOLUTION_12B;
  hadc1.Init.ScanConvMode = DISABLE;
  hadc1.Init.ContinuousConvMode = DISABLE;
  hadc1.Init.DiscontinuousConvMode = DISABLE;
  hadc1.Init.ExternalTrigConvEdge = ADC_EXTERNALTRIGCONVEDGE_RISING;
  hadc1.Init.ExternalTrigConv = ADC_EXTERNALTRIGCONV_T4_CC4;
  hadc1.Init.DataAlign = ADC_DATAALIGN_RIGHT;
  hadc1.Init.NbrOfConversion = 1;
  hadc1.Init.DMAContinuousRequests = DISABLE;
  hadc1.Init.EOCSelection = ADC_EOC_SINGLE_CONV;
  if (HAL_ADC_Init(&hadc1) != HAL_OK)
  {
    Error_Handler();
  }

  /** Configure for the selected ADC regular channel its corresponding rank in the sequencer and its sample time.
  */
  sConfig.Channel = ADC_CHANNEL_4;
  sConfig.Rank = 1;
  sConfig.SamplingTime = ADC_SAMPLETIME_28CYCLES;
  if (HAL_ADC_ConfigChannel(&hadc1, &sConfig) != HAL_OK)
  {
    Error_Handler();
  }

}

static void MX_TIM2_Init(void)
{

  TIM_SlaveConfigTypeDef sSlaveConfig = {0};
  TIM_MasterConfigTypeDef sMasterConfig = {0};
  TIM_OC_InitTypeDef sConfigOC = {0};

  htim2.Instance = TIM2;
  htim2.Init.Prescaler = 0;
  htim2.Init.CounterMode = TIM_COUNTERMODE_UP;
  htim2.Init.Period = 720200;
  htim2.Init.ClockDivision = TIM_CLOCKDIVISION_DIV1;
  htim2.Init.AutoReloadPreload = TIM_AUTORELOAD_PRELOAD_DISABLE;
  if (HAL_TIM_Base_Init(&htim2) != HAL_OK)
  {
    Error_Handler();
  }
  if (HAL_TIM_OC_Init(&htim2) != HAL_OK)
  {
    Error_Handler();
  }
  sSlaveConfig.SlaveMode = TIM_SLAVEMODE_EXTERNAL1;
  sSlaveConfig.InputTrigger = TIM_TS_ITR2;
  if (HAL_TIM_SlaveConfigSynchro(&htim2, &sSlaveConfig) != HAL_OK)
  {
    Error_Handler();
  }
  sMasterConfig.MasterOutputTrigger = TIM_TRGO_RESET;
  sMasterConfig.MasterSlaveMode = TIM_MASTERSLAVEMODE_DISABLE;
  if (HAL_TIMEx_MasterConfigSynchronization(&htim2, &sMasterConfig) != HAL_OK)
  {
    Error_Handler();
  }
  sConfigOC.OCMode = TIM_OCMODE_TOGGLE;
  sConfigOC.Pulse = 50;
  sConfigOC.OCPolarity = TIM_OCPOLARITY_LOW;
  sConfigOC.OCFastMode = TIM_OCFAST_DISABLE;
  if (HAL_TIM_OC_ConfigChannel(&htim2, &sConfigOC, TIM_CHANNEL_2) != HAL_OK)
  {
    Error_Handler();
  }
  sConfigOC.Pulse = 0;
  sConfigOC.OCPolarity = TIM_OCPOLARITY_HIGH;
  if (HAL_TIM_OC_ConfigChannel(&htim2, &sConfigOC, TIM_CHANNEL_3) != HAL_OK)
  {
    Error_Handler();
  }
  HAL_TIM_MspPostInit(&htim2);

}

static void MX_TIM3_Init(void)
{

  TIM_ClockConfigTypeDef sClockSourceConfig = {0};
  TIM_MasterConfigTypeDef sMasterConfig = {0};
  TIM_OC_InitTypeDef sConfigOC = {0};

  htim3.Instance = TIM3;
  htim3.Init.Prescaler = 0;
  htim3.Init.CounterMode = TIM_COUNTERMODE_UP;
  htim3.Init.Period = 44;
  htim3.Init.ClockDivision = TIM_CLOCKDIVISION_DIV1;
  htim3.Init.AutoReloadPreload = TIM_AUTORELOAD_PRELOAD_DISABLE;
  if (HAL_TIM_Base_Init(&htim3) != HAL_OK)
  {
    Error_Handler();
  }
  sClockSourceConfig.ClockSource = TIM_CLOCKSOURCE_INTERNAL;
  if (HAL_TIM_ConfigClockSource(&htim3, &sClockSourceConfig) != HAL_OK)
  {
    Error_Handler();
  }
  if (HAL_TIM_PWM_Init(&htim3) != HAL_OK)
  {
    Error_Handler();
  }
  sMasterConfig.MasterOutputTrigger = TIM_TRGO_UPDATE;
  sMasterConfig.MasterSlaveMode = TIM_MASTERSLAVEMODE_ENABLE;
  if (HAL_TIMEx_MasterConfigSynchronization(&htim3, &sMasterConfig) != HAL_OK)
  {
    Error_Handler();
  }
  sConfigOC.OCMode = TIM_OCMODE_PWM1;
  sConfigOC.Pulse = 22;
  sConfigOC.OCPolarity = TIM_OCPOLARITY_HIGH;
  sConfigOC.OCFastMode = TIM_OCFAST_DISABLE;
  if (HAL_TIM_PWM_ConfigChannel(&htim3, &sConfigOC, TIM_CHANNEL_1) != HAL_OK)
  {
    Error_Handler();
  }
  HAL_TIM_MspPostInit(&htim3);

}

static void MX_TIM4_Init(void)
{

  TIM_SlaveConfigTypeDef sSlaveConfig = {0};
  TIM_MasterConfigTypeDef sMasterConfig = {0};
  TIM_OC_InitTypeDef sConfigOC = {0};

  htim4.Instance = TIM4;
  htim4.Init.Prescaler = 0;
  htim4.Init.CounterMode = TIM_COUNTERMODE_UP;
  htim4.Init.Period = 3;
  htim4.Init.ClockDivision = TIM_CLOCKDIVISION_DIV1;
  htim4.Init.AutoReloadPreload = TIM_AUTORELOAD_PRELOAD_DISABLE;
  if (HAL_TIM_Base_Init(&htim4) != HAL_OK)
  {
    Error_Handler();
  }
  if (HAL_TIM_PWM_Init(&htim4) != HAL_OK)
  {
    Error_Handler();
  }
  sSlaveConfig.SlaveMode = TIM_SLAVEMODE_EXTERNAL1;
  sSlaveConfig.InputTrigger = TIM_TS_ITR2;
  if (HAL_TIM_SlaveConfigSynchro(&htim4, &sSlaveConfig) != HAL_OK)
  {
    Error_Handler();
  }
  sMasterConfig.MasterOutputTrigger = TIM_TRGO_RESET;
  sMasterConfig.MasterSlaveMode = TIM_MASTERSLAVEMODE_DISABLE;
  if (HAL_TIMEx_MasterConfigSynchronization(&htim4, &sMasterConfig) != HAL_OK)
  {
    Error_Handler();
  }
  sConfigOC.OCMode = TIM_OCMODE_PWM1;
  sConfigOC.Pulse = 3;
  sConfigOC.OCPolarity = TIM_OCPOLARITY_LOW;
  sConfigOC.OCFastMode = TIM_OCFAST_DISABLE;
  if (HAL_TIM_PWM_ConfigChannel(&htim4, &sConfigOC, TIM_CHANNEL_4) != HAL_OK)
  {
    Error_Handler();
  }
  HAL_TIM_MspPostInit(&htim4);

}

static void MX_USART6_UART_Init(void)
{

  huart6.Instance = USART6;
  huart6.Init.BaudRate = 460800;
  huart6.Init.WordLength = UART_WORDLENGTH_8B;
  huart6.Init.StopBits = UART_STOPBITS_1;
  huart6.Init.Parity = UART_PARITY_NONE;
  huart6.Init.Mode = UART_MODE_TX_RX;
  huart6.Init.HwFlowCtl = UART_HWCONTROL_NONE;
  huart6.Init.OverSampling = UART_OVERSAMPLING_16;
  if (HAL_UART_Init(&huart6) != HAL_OK)
  {
    Error_Handler();
  }

}

static void MX_DMA_Init(void)
{

  /* DMA controller clock enable */
  __HAL_RCC_DMA1_CLK_ENABLE();
  __HAL_RCC_DMA2_CLK_ENABLE();

  /* DMA interrupt init */
  /* DMA1_Stream1_IRQn interrupt configuration */
  HAL_NVIC_SetPriority(DMA1_Stream1_IRQn, 0, 0);
  HAL_NVIC_EnableIRQ(DMA1_Stream1_IRQn);
  /* DMA1_Stream6_IRQn interrupt configuration */
  HAL_NVIC_SetPriority(DMA1_Stream6_IRQn, 0, 0);
  HAL_NVIC_EnableIRQ(DMA1_Stream6_IRQn);
  /* DMA2_Stream0_IRQn interrupt configuration */
  HAL_NVIC_SetPriority(DMA2_Stream0_IRQn, 0, 0);
  HAL_NVIC_EnableIRQ(DMA2_Stream0_IRQn);
  /* DMA2_Stream1_IRQn interrupt configuration */
  HAL_NVIC_SetPriority(DMA2_Stream1_IRQn, 0, 0);
  HAL_NVIC_EnableIRQ(DMA2_Stream1_IRQn);
  /* DMA2_Stream6_IRQn interrupt configuration */
  HAL_NVIC_SetPriority(DMA2_Stream6_IRQn, 0, 0);
  HAL_NVIC_EnableIRQ(DMA2_Stream6_IRQn);

}

/* FMC initialization function */
static void MX_FMC_Init(void)
{

  FMC_SDRAM_TimingTypeDef SdramTiming = {0};

  /** Perform the SDRAM1 memory initialization sequence
  */
  hsdram1.Instance = FMC_SDRAM_DEVICE;
  /* hsdram1.Init */
  hsdram1.Init.SDBank = FMC_SDRAM_BANK1;
  hsdram1.Init.ColumnBitsNumber = FMC_SDRAM_COLUMN_BITS_NUM_8;
  hsdram1.Init.RowBitsNumber = FMC_SDRAM_ROW_BITS_NUM_12;
  hsdram1.Init.MemoryDataWidth = FMC_SDRAM_MEM_BUS_WIDTH_32;
  hsdram1.Init.InternalBankNumber = FMC_SDRAM_INTERN_BANKS_NUM_4;
  hsdram1.Init.CASLatency = FMC_SDRAM_CAS_LATENCY_3;
  hsdram1.Init.WriteProtection = FMC_SDRAM_WRITE_PROTECTION_DISABLE;
  hsdram1.Init.SDClockPeriod = FMC_SDRAM_CLOCK_PERIOD_2;
  hsdram1.Init.ReadBurst = FMC_SDRAM_RBURST_ENABLE;
  hsdram1.Init.ReadPipeDelay = FMC_SDRAM_RPIPE_DELAY_0;
  /* SdramTiming */
  SdramTiming.LoadToActiveDelay = 2;
  SdramTiming.ExitSelfRefreshDelay = 6;
  SdramTiming.SelfRefreshTime = 4;
  SdramTiming.RowCycleDelay = 6;
  SdramTiming.WriteRecoveryTime = 2;
  SdramTiming.RPDelay = 2;
  SdramTiming.RCDDelay = 2;

  if (HAL_SDRAM_Init(&hsdram1, &SdramTiming) != HAL_OK)
  {
    Error_Handler( );
  }

  /* USER CODE BEGIN FMC_Init 2 */
  SDRAM_Initialization_Sequence(&hsdram1);
  /* USER CODE END FMC_Init 2 */
}

static void MX_GPIO_Init(void)
{
  GPIO_InitTypeDef GPIO_InitStruct = {0};

  /* GPIO Ports Clock Enable */
  __HAL_RCC_GPIOE_CLK_ENABLE();
  __HAL_RCC_GPIOG_CLK_ENABLE();
  __HAL_RCC_GPIOB_CLK_ENABLE();
  __HAL_RCC_GPIOC_CLK_ENABLE();
  __HAL_RCC_GPIOA_CLK_ENABLE();
  __HAL_RCC_GPIOD_CLK_ENABLE();
  __HAL_RCC_GPIOI_CLK_ENABLE();
  __HAL_RCC_GPIOF_CLK_ENABLE();
  __HAL_RCC_GPIOK_CLK_ENABLE();
  __HAL_RCC_GPIOH_CLK_ENABLE();
  __HAL_RCC_GPIOJ_CLK_ENABLE();

  /*Configure GPIO pin Output Level */
  HAL_GPIO_WritePin(GPIOE, SPKR_HP_Pin|AUDIO_RST_Pin, GPIO_PIN_RESET);

  /*Configure GPIO pin Output Level */
  HAL_GPIO_WritePin(GPIOD, LED3_Pin|LED2_Pin, GPIO_PIN_RESET);

  /*Configure GPIO pin Output Level */
  HAL_GPIO_WritePin(LED4_GPIO_Port, LED4_Pin, GPIO_PIN_RESET);

  /*Configure GPIO pin Output Level */
  HAL_GPIO_WritePin(LED1_GPIO_Port, LED1_Pin, GPIO_PIN_RESET);

  /*Configure GPIO pin Output Level */
  HAL_GPIO_WritePin(GPIOB, OTG_FS1_PowerSwitchOn_Pin|EXT_RESET_Pin, GPIO_PIN_RESET);

  /*Configure GPIO pin Output Level */
  HAL_GPIO_WritePin(GPIOH, GPIO_PIN_7, GPIO_PIN_RESET);

  /*Configure GPIO pin Output Level */
  HAL_GPIO_WritePin(LCD_BL_CTRL_GPIO_Port, LCD_BL_CTRL_Pin, GPIO_PIN_RESET);

  /*Configure GPIO pins : SAI1_FSA_Pin SAI1_SCKA_Pin */
  GPIO_InitStruct.Pin = SAI1_FSA_Pin|SAI1_SCKA_Pin;
  GPIO_InitStruct.Mode = GPIO_MODE_AF_PP;
  GPIO_InitStruct.Pull = GPIO_NOPULL;
  GPIO_InitStruct.Speed = GPIO_SPEED_FREQ_LOW;
  GPIO_InitStruct.Alternate = GPIO_AF6_SAI1;
  HAL_GPIO_Init(GPIOE, &GPIO_InitStruct);

  /*Configure GPIO pins : SPKR_HP_Pin AUDIO_RST_Pin */
  GPIO_InitStruct.Pin = SPKR_HP_Pin|AUDIO_RST_Pin;
  GPIO_InitStruct.Mode = GPIO_MODE_OUTPUT_PP;
  GPIO_InitStruct.Pull = GPIO_NOPULL;
  GPIO_InitStruct.Speed = GPIO_SPEED_FREQ_LOW;
  HAL_GPIO_Init(GPIOE, &GPIO_InitStruct);

  /*Configure GPIO pins : uSD_CLK_Pin uSD_D3_Pin uSD_D2_Pin uSD_D1_Pin
                           uSD_D0_Pin */
  GPIO_InitStruct.Pin = uSD_CLK_Pin|uSD_D3_Pin|uSD_D2_Pin|uSD_D1_Pin
                          |uSD_D0_Pin;
  GPIO_InitStruct.Mode = GPIO_MODE_AF_PP;
  GPIO_InitStruct.Pull = GPIO_NOPULL;
  GPIO_InitStruct.Speed = GPIO_SPEED_FREQ_VERY_HIGH;
  GPIO_InitStruct.Alternate = GPIO_AF12_SDIO;
  HAL_GPIO_Init(GPIOC, &GPIO_InitStruct);

  /*Configure GPIO pin : OTG_FS1_OverCurrent_Pin */
  GPIO_InitStruct.Pin = OTG_FS1_OverCurrent_Pin;
  GPIO_InitStruct.Mode = GPIO_MODE_IT_RISING;
  GPIO_InitStruct.Pull = GPIO_NOPULL;
  HAL_GPIO_Init(OTG_FS1_OverCurrent_GPIO_Port, &GPIO_InitStruct);

  /*Configure GPIO pin : QSPI_BK1_NCS_Pin */
  GPIO_InitStruct.Pin = QSPI_BK1_NCS_Pin;
  GPIO_InitStruct.Mode = GPIO_MODE_AF_PP;
  GPIO_InitStruct.Pull = GPIO_NOPULL;
  GPIO_InitStruct.Speed = GPIO_SPEED_FREQ_VERY_HIGH;
  GPIO_InitStruct.Alternate = GPIO_AF10_QSPI;
  HAL_GPIO_Init(QSPI_BK1_NCS_GPIO_Port, &GPIO_InitStruct);

  /*Configure GPIO pin : MIC_DATA_Pin */
  GPIO_InitStruct.Pin = MIC_DATA_Pin;
  GPIO_InitStruct.Mode = GPIO_MODE_AF_PP;
  GPIO_InitStruct.Pull = GPIO_NOPULL;
  GPIO_InitStruct.Speed = GPIO_SPEED_FREQ_LOW;
  GPIO_InitStruct.Alternate = GPIO_AF6_SAI1;
  HAL_GPIO_Init(MIC_DATA_GPIO_Port, &GPIO_InitStruct);

  /*Configure GPIO pins : USB_FS1_P_Pin USB_FS1_N_Pin USB_FS1_ID_Pin */
  GPIO_InitStruct.Pin = USB_FS1_P_Pin|USB_FS1_N_Pin|USB_FS1_ID_Pin;
  GPIO_InitStruct.Mode = GPIO_MODE_AF_PP;
  GPIO_InitStruct.Pull = GPIO_NOPULL;
  GPIO_InitStruct.Speed = GPIO_SPEED_FREQ_VERY_HIGH;
  GPIO_InitStruct.Alternate = GPIO_AF10_OTG_FS;
  HAL_GPIO_Init(GPIOA, &GPIO_InitStruct);

  /*Configure GPIO pins : LED3_Pin LED2_Pin */
  GPIO_InitStruct.Pin = LED3_Pin|LED2_Pin;
  GPIO_InitStruct.Mode = GPIO_MODE_OUTPUT_OD;
  GPIO_InitStruct.Pull = GPIO_NOPULL;
  GPIO_InitStruct.Speed = GPIO_SPEED_FREQ_LOW;
  HAL_GPIO_Init(GPIOD, &GPIO_InitStruct);

  /*Configure GPIO pin : LED4_Pin */
  GPIO_InitStruct.Pin = LED4_Pin;
  GPIO_InitStruct.Mode = GPIO_MODE_OUTPUT_OD;
  GPIO_InitStruct.Pull = GPIO_NOPULL;
  GPIO_InitStruct.Speed = GPIO_SPEED_FREQ_LOW;
  HAL_GPIO_Init(LED4_GPIO_Port, &GPIO_InitStruct);

  /*Configure GPIO pin : uSD_CMD_Pin */
  GPIO_InitStruct.Pin = uSD_CMD_Pin;
  GPIO_InitStruct.Mode = GPIO_MODE_AF_PP;
  GPIO_InitStruct.Pull = GPIO_NOPULL;
  GPIO_InitStruct.Speed = GPIO_SPEED_FREQ_VERY_HIGH;
  GPIO_InitStruct.Alternate = GPIO_AF12_SDIO;
  HAL_GPIO_Init(uSD_CMD_GPIO_Port, &GPIO_InitStruct);

  /*Configure GPIO pins : I2C2_SCL_Pin I2C2_SDA_Pin */
  GPIO_InitStruct.Pin = I2C2_SCL_Pin|I2C2_SDA_Pin;
  GPIO_InitStruct.Mode = GPIO_MODE_AF_OD;
  GPIO_InitStruct.Pull = GPIO_PULLUP;
  GPIO_InitStruct.Speed = GPIO_SPEED_FREQ_VERY_HIGH;
  GPIO_InitStruct.Alternate = GPIO_AF4_I2C2;
  HAL_GPIO_Init(GPIOH, &GPIO_InitStruct);

  /*Configure GPIO pin : SAI1_MCLKA_Pin */
  GPIO_InitStruct.Pin = SAI1_MCLKA_Pin;
  GPIO_InitStruct.Mode = GPIO_MODE_AF_PP;
  GPIO_InitStruct.Pull = GPIO_NOPULL;
  GPIO_InitStruct.Speed = GPIO_SPEED_FREQ_LOW;
  GPIO_InitStruct.Alternate = GPIO_AF6_SAI1;
  HAL_GPIO_Init(SAI1_MCLKA_GPIO_Port, &GPIO_InitStruct);

  /*Configure GPIO pin : LED1_Pin */
  GPIO_InitStruct.Pin = LED1_Pin;
  GPIO_InitStruct.Mode = GPIO_MODE_OUTPUT_OD;
  GPIO_InitStruct.Pull = GPIO_NOPULL;
  GPIO_InitStruct.Speed = GPIO_SPEED_FREQ_LOW;
  HAL_GPIO_Init(LED1_GPIO_Port, &GPIO_InitStruct);

  /*Configure GPIO pins : QSPI_BK1_IO2_Pin QSPI_BK1_IO3_Pin QSPI_CLK_Pin */
  GPIO_InitStruct.Pin = QSPI_BK1_IO2_Pin|QSPI_BK1_IO3_Pin|QSPI_CLK_Pin;
  GPIO_InitStruct.Mode = GPIO_MODE_AF_PP;
  GPIO_InitStruct.Pull = GPIO_NOPULL;
  GPIO_InitStruct.Speed = GPIO_SPEED_FREQ_VERY_HIGH;
  GPIO_InitStruct.Alternate = GPIO_AF9_QSPI;
  HAL_GPIO_Init(GPIOF, &GPIO_InitStruct);

  /*Configure GPIO pins : QSPI_BK1_IO1_Pin QSPI_BK1_IO0_Pin */
  GPIO_InitStruct.Pin = QSPI_BK1_IO1_Pin|QSPI_BK1_IO0_Pin;
  GPIO_InitStruct.Mode = GPIO_MODE_AF_PP;
  GPIO_InitStruct.Pull = GPIO_NOPULL;
  GPIO_InitStruct.Speed = GPIO_SPEED_FREQ_VERY_HIGH;
  GPIO_InitStruct.Alternate = GPIO_AF10_QSPI;
  HAL_GPIO_Init(GPIOF, &GPIO_InitStruct);

  /*Configure GPIO pins : OTG_FS1_PowerSwitchOn_Pin EXT_RESET_Pin */
  GPIO_InitStruct.Pin = OTG_FS1_PowerSwitchOn_Pin|EXT_RESET_Pin;
  GPIO_InitStruct.Mode = GPIO_MODE_OUTPUT_PP;
  GPIO_InitStruct.Pull = GPIO_NOPULL;
  GPIO_InitStruct.Speed = GPIO_SPEED_FREQ_LOW;
  HAL_GPIO_Init(GPIOB, &GPIO_InitStruct);

  /*Configure GPIO pin : uSD_Detect_Pin */
  GPIO_InitStruct.Pin = uSD_Detect_Pin;
  GPIO_InitStruct.Mode = GPIO_MODE_INPUT;
  GPIO_InitStruct.Pull = GPIO_NOPULL;
  HAL_GPIO_Init(uSD_Detect_GPIO_Port, &GPIO_InitStruct);

  /*Configure GPIO pin : LCD_INT_Pin */
  GPIO_InitStruct.Pin = LCD_INT_Pin;
  GPIO_InitStruct.Mode = GPIO_MODE_IT_RISING;
  GPIO_InitStruct.Pull = GPIO_NOPULL;
  HAL_GPIO_Init(LCD_INT_GPIO_Port, &GPIO_InitStruct);

  /*Configure GPIO pin : PH7 */
  GPIO_InitStruct.Pin = GPIO_PIN_7;
  GPIO_InitStruct.Mode = GPIO_MODE_OUTPUT_PP;
  GPIO_InitStruct.Pull = GPIO_NOPULL;
  GPIO_InitStruct.Speed = GPIO_SPEED_FREQ_LOW;
  HAL_GPIO_Init(GPIOH, &GPIO_InitStruct);

  /*Configure GPIO pin : DSI_TE_Pin */
  GPIO_InitStruct.Pin = DSI_TE_Pin;
  GPIO_InitStruct.Mode = GPIO_MODE_AF_PP;
  GPIO_InitStruct.Pull = GPIO_NOPULL;
  GPIO_InitStruct.Speed = GPIO_SPEED_FREQ_VERY_HIGH;
  GPIO_InitStruct.Alternate = GPIO_AF13_DSI;
  HAL_GPIO_Init(DSI_TE_GPIO_Port, &GPIO_InitStruct);

  /*Configure GPIO pins : STLK_RX_Pin STLK_TX_Pin */
  GPIO_InitStruct.Pin = STLK_RX_Pin|STLK_TX_Pin;
  GPIO_InitStruct.Mode = GPIO_MODE_AF_PP;
  GPIO_InitStruct.Pull = GPIO_PULLUP;
  GPIO_InitStruct.Speed = GPIO_SPEED_FREQ_VERY_HIGH;
  GPIO_InitStruct.Alternate = GPIO_AF7_USART3;
  HAL_GPIO_Init(GPIOB, &GPIO_InitStruct);

  /*Configure GPIO pin : LCD_BL_CTRL_Pin */
  GPIO_InitStruct.Pin = LCD_BL_CTRL_Pin;
  GPIO_InitStruct.Mode = GPIO_MODE_OUTPUT_PP;
  GPIO_InitStruct.Pull = GPIO_NOPULL;
  GPIO_InitStruct.Speed = GPIO_SPEED_FREQ_LOW;
  HAL_GPIO_Init(LCD_BL_CTRL_GPIO_Port, &GPIO_InitStruct);

  /*Configure GPIO pin : PB14 */
  GPIO_InitStruct.Pin = GPIO_PIN_14;
  GPIO_InitStruct.Mode = GPIO_MODE_AF_PP;
  GPIO_InitStruct.Pull = GPIO_NOPULL;
  GPIO_InitStruct.Speed = GPIO_SPEED_FREQ_LOW;
  GPIO_InitStruct.Alternate = GPIO_AF1_TIM1;
  HAL_GPIO_Init(GPIOB, &GPIO_InitStruct);

}

void HAL_TIM_PeriodElapsedCallback(TIM_HandleTypeDef *htim)
{
  if (htim->Instance == TIM6)
  {
    HAL_IncTick();
  }
}

void Error_Handler(void)
{
  __disable_irq();
  while (1)
  {
  }
}
